# ESP32-C5 register map
Vendor: ESPRESSIF SYSTEMS (SHANGHAI) CO., LTD.; Series: ESP32 C-Series; File version: 1
CPU: RV32IMAC r0p0, little endian, no MPU, no FPU, 0 interrupt priority bits
Address unit: 32 bits
Registers are 32-bit, read-write, reset 0x0 unless marked. A register's access mark holds for its fields unless they carry their own. Offsets are from the block's base; [hi:lo] are bit positions; {n}, {i} and the like mark numbered series.

## LP_AON — LP_AON Peripheral
Base 0x600B1000
0x00 STORE0 — store the software massege0 in always-on field
  [31:0] DATA
{0x0+4i} STORE{i} (i=1..9) — store the software massege{i} in always-on field
  [31:0] DATA — store the software massege0 in always-on field
0x28 GPIO_MUX — select the lp io controlled by hp iomux or lp iomux
  [7:0] SEL — select the lp io 0~7 controlled by hp iomux or lp iomux 1: controlled by lp iomux 0: controlled by hp iomux
0x2C GPIO_HOLD0 — configure all io hold
  [31:0] GPIO_HOLD0 — configure io0~28 hold enable,when io in hold status, all io configure and output will be latch , input function is useful
0x30 GPIO_HOLD1 — reserved
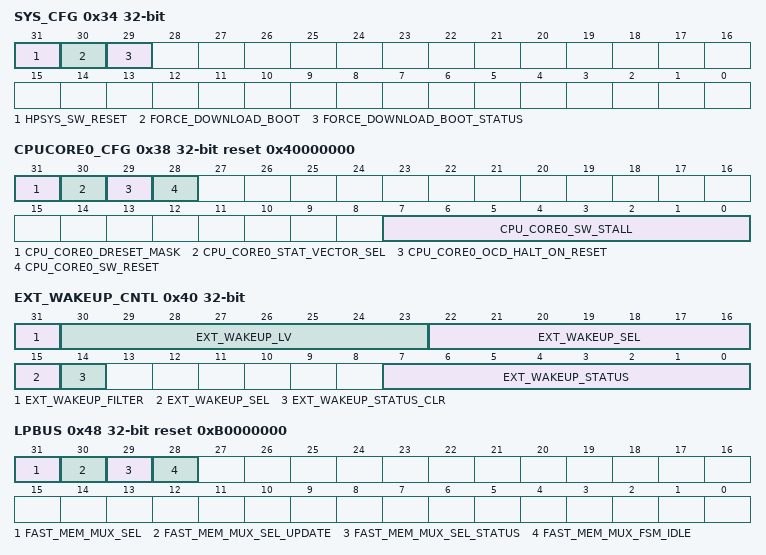
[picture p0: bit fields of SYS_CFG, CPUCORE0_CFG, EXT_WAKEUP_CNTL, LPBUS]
0x34 SYS_CFG access per field — configure system register
  [31] HPSYS_SW_RESET wo — enable hp system reset by software or not 1: reset 0: no operation
  [30] FORCE_DOWNLOAD_BOOT rw — enable chip entry download mode or not 1: enable 0: no operation
  [29] FORCE_DOWNLOAD_BOOT_STATUS ro — get force download mode status
0x38 CPUCORE0_CFG access per field reset 0x40000000 — configure core reset register
  [31] CPU_CORE0_DRESET_MASK rw — disable bypass core dreset 1: enable bypass 0: disable bypass
  [30] CPU_CORE0_STAT_VECTOR_SEL rw — configure core boot address 1: ROM 0: lp memory
  [29] CPU_CORE0_OCD_HALT_ON_RESET rw — reserved
  [28] CPU_CORE0_SW_RESET wo — enable core reset by software 1: reset 0: no operation
  [7:0] CPU_CORE0_SW_STALL rw — enable cpu entry stall status 0x86: entry stall status Others : no operation
0x3C IO_MUX — configure hp iomux reset bypass
  [31] RESET_DISABLE — bypass hp iomux reset from hp system reset event 1: bypass 0: no operation
0x40 EXT_WAKEUP_CNTL access per field — configure alwayson external io wakeup
  [31] EXT_WAKEUP_FILTER rw — enable external filter or not 1: enable 0: disable
  [30:23] EXT_WAKEUP_LV rw — select external wakeup io level 1: io high level wakeup 0: io low level wakeup
  [22:15] EXT_WAKEUP_SEL rw — enable io0~7 bit map use to external wakeup 1: enable 0: disable
  [14] EXT_WAKEUP_STATUS_CLR wo — clear external wakeup status 1: clear 0: no operation
  [7:0] EXT_WAKEUP_STATUS ro — get external wakeup status bitmap
0x44 USB — configure usb reset bypass
  [31] RESET_DISABLE — bypass usb reset from hp system reset event 1: bypass 0: no operation
0x48 LPBUS access per field reset 0xB0000000 — Select lp memory bus
  [31] FAST_MEM_MUX_SEL rw — select lp memory bus is high speed mode or low speed mode 1: high speed from hp system ahb 0: low speed from lp system
  [30] FAST_MEM_MUX_SEL_UPDATE wo — enable reg_fast_mem_sel configure 1: enable 0: no operation
  [29] FAST_MEM_MUX_SEL_STATUS ro — get current lp memory bus mode
  [28] FAST_MEM_MUX_FSM_IDLE ro — get current lp memory bus fsm status
0x4C SDIO_ACTIVE reset 0x2800000 — configure sdio act dnum
  [31:22] SDIO_ACT_DNUM — reserved
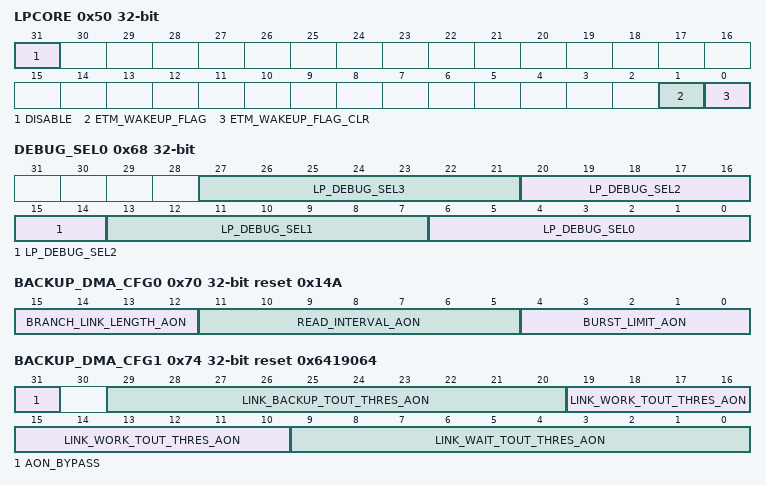
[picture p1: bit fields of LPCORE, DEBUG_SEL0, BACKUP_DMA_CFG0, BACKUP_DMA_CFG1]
0x50 LPCORE access per field — configure etm wakeup register
  [31] DISABLE rw — disable lp core 1:disable 0:no operation
  [1] ETM_WAKEUP_FLAG rw — latch etmwakeup event
  [0] ETM_WAKEUP_FLAG_CLR wo — clear etm wakeup latch
0x54 SAR_CCT — configure sar cct
  [31:29] SAR2_PWDET_CCT
0x58 MODEM_BUS — configure modem sync bridge
  [31] MODEM_SYNC_BRIDGE_EN — enable modem sync bridge or not 1: enable 0: disable
0x60 SPRAM_CTRL reset 0x2070 — configure lp memory power status
  [31:0] SPRAM_MEM_AUX_CTRL
0x64 SPRF_CTRL reset 0x2070 — configure memory in lp system power status
  [31:0] SPRF_MEM_AUX_CTRL
0x68 DEBUG_SEL0 — reserved
  [7n+6:7n] LP_DEBUG_SEL{n} (n=0..3) — need des
0x6C DEBUG_SEL1 — need des
  [6:0] LP_DEBUG_SEL4
0x70 BACKUP_DMA_CFG0 reset 0x14A — configure regdma always on register
  [15:12] BRANCH_LINK_LENGTH_AON — Set this field to configure link address.
  [11:5] READ_INTERVAL_AON — Set this field to configure read registers' interval time in reading mode.
  [4:0] BURST_LIMIT_AON — Set this field to configure max value of burst in signle transfer.
0x74 BACKUP_DMA_CFG1 reset 0x6419064 — configure regdma always on register
  [31] AON_BYPASS — reserved
  [29:20] LINK_BACKUP_TOUT_THRES_AON — Set this field to configure maximum waiting time in backup mode.
  [19:10] LINK_WORK_TOUT_THRES_AON — Set this field to configure maximum waiting time in waiting mode.
  [9:0] LINK_WAIT_TOUT_THRES_AON — Set this field to configure the number of consecutive links of link list.
0x78 BACKUP_DMA_CFG2 — configure regdma always on register
  [31:0] LINK_ADDR_AON — Set this field to configure link address.
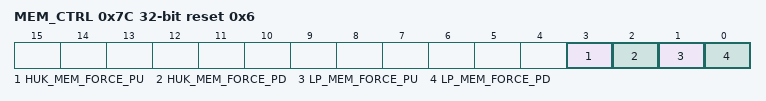
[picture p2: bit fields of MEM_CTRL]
0x7C MEM_CTRL reset 0x6 — configure rmemory power in lp system register
  [3] HUK_MEM_FORCE_PU — force on huk memory
  [2] HUK_MEM_FORCE_PD — force off huk memory
  [1] LP_MEM_FORCE_PU — force on lp memory
  [0] LP_MEM_FORCE_PD — force off lp memory
0x3FC DATE — reserved
